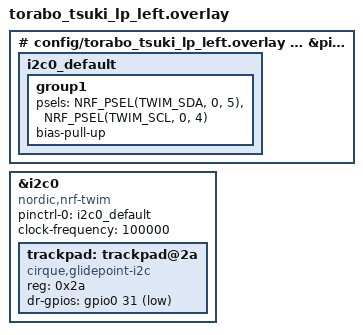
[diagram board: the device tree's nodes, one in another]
# config/torabo_tsuki_lp_left.overlay に貼り付けるコード
&pinctrl {
    i2c0_default: i2c0_default {
        group1 {
            psels = <NRF_PSEL(TWIM_SDA, 0, 5)>,
                    <NRF_PSEL(TWIM_SCL, 0, 4)>;
            bias-pull-up;
        };
    };
};

&i2c0 {
    status = "okay";
    compatible = "nordic,nrf-twim";
    pinctrl-0 = <&i2c0_default>;
    pinctrl-names = "default";
    clock-frequency = <100000>;

    trackpad: trackpad@2a {
        compatible = "cirque,glidepoint-i2c";
        reg = <0x2a>;
        status = "okay";
        dr-gpios = <&gpio0 31 (GPIO_ACTIVE_LOW | GPIO_PULL_UP)>;
    };
};
